# RockChip_RK3588 register map
Vendor: RockChip Electronics Co., Ltd.; Series: RK3588; File version: 0.1
Registers are 32-bit, read-write, no defined reset value unless marked. A register's access mark holds for its fields unless they carry their own. Offsets are from the block's base; [hi:lo] are bit positions; {n}, {i} and the like mark numbered series.

## PMU (part 2 of 3)
Base 0xFD8D0000
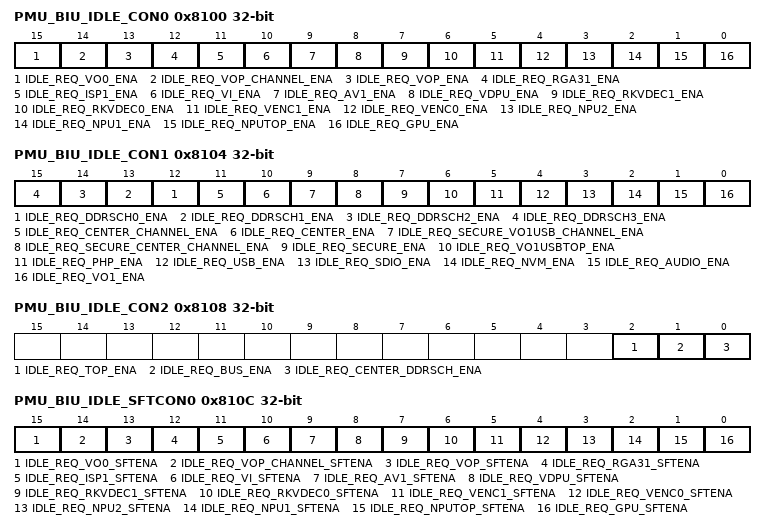
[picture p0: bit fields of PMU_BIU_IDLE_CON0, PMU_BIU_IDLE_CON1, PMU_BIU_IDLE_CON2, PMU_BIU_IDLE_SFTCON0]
0x8100 PMU_BIU_IDLE_CON0 — BIU idle request hardware control register 0
  [all] fields
    0=DISABLE; 1=ENABLE
  [15] IDLE_REQ_VO0_ENA — Enable sending idle request to BIU_VO0 by hardware.
  [14] IDLE_REQ_VOP_CHANNEL_ENA — Enable sending idle request to BIU_VOP_CHANNEL by hardware.
  [13] IDLE_REQ_VOP_ENA — Enable sending idle request to BIU_VOP by hardware.
  [12] IDLE_REQ_RGA31_ENA — Enable sending idle request to BIU_RGA31 by hardware.
  [11] IDLE_REQ_ISP1_ENA — Enable sending idle request to BIU_ISP1 by hardware.
  [10] IDLE_REQ_VI_ENA — Enable sending idle request to BIU_VI by hardware.
  [9] IDLE_REQ_AV1_ENA — Enable sending idle request to BIU_AV1 by hardware.
  [8] IDLE_REQ_VDPU_ENA — Enable sending idle request to BIU_VDPU by hardware.
  [7] IDLE_REQ_RKVDEC1_ENA — Enable sending idle request to BIU_RKVDEC1 by hardware.
  [6] IDLE_REQ_RKVDEC0_ENA — Enable sending idle request to BIU_RKVDEC0 by hardware.
  [5] IDLE_REQ_VENC1_ENA — Enable sending idle request to BIU_VENC1 by hardware.
  [4] IDLE_REQ_VENC0_ENA — Enable sending idle request to BIU_VENC0 by hardware.
  [3] IDLE_REQ_NPU2_ENA — Enable sending idle request to BIU_NPU2 by hardware.
  [2] IDLE_REQ_NPU1_ENA — Enable sending idle request to BIU_NPU1 by hardware.
  [1] IDLE_REQ_NPUTOP_ENA — Enable sending idle request to BIU_NPUTOP by hardware.
  [0] IDLE_REQ_GPU_ENA — Enable sending idle request to BIU_GPU by hardware.
0x8104 PMU_BIU_IDLE_CON1 — BIU idle request hardware control register 1
  [all] fields
    0=DISABLE; 1=ENABLE
  [n+12] IDLE_REQ_DDRSCH{n}_ENA (n=0..3) — Enable sending idle request to BIU_DDRSCH{n} by hardware.
  [11] IDLE_REQ_CENTER_CHANNEL_ENA — Enable sending idle request to BIU_CENTER_CHANNEL by hardware.
  [10] IDLE_REQ_CENTER_ENA — Enable sending idle request to BIU_CENTER by hardware.
  [9] IDLE_REQ_SECURE_VO1USB_CHANNEL_ENA — Enable sending idle request to BIU_SECURE_VO1USB_CHANNEL by hardware.
  [8] IDLE_REQ_SECURE_CENTER_CHANNEL_ENA — Enable sending idle request to BIU_SECURE_CENTER_CHANNEL by hardware.
  [7] IDLE_REQ_SECURE_ENA — Enable sending idle request to BIU_SECURE by hardware.
  [6] IDLE_REQ_VO1USBTOP_ENA — Enable sending idle request to BIU_VO1USBTOP by hardware.
  [5] IDLE_REQ_PHP_ENA — Enable sending idle request to BIU_PHP by hardware.
  [4] IDLE_REQ_USB_ENA — Enable sending idle request to BIU_USB by hardware.
  [3] IDLE_REQ_SDIO_ENA — Enable sending idle request to BIU_SDIO by hardware.
  [2] IDLE_REQ_NVM_ENA — Enable sending idle request to BIU_NVM by hardware.
  [1] IDLE_REQ_AUDIO_ENA — Enable sending idle request to BIU_AUDIO by hardware.
  [0] IDLE_REQ_VO1_ENA — Enable sending idle request to BIU_VO1 by hardware.
0x8108 PMU_BIU_IDLE_CON2 — BIU idle request hardware control register 2
  [all] fields
    0=DISABLE; 1=ENABLE
  [2] IDLE_REQ_TOP_ENA — Enable sending idle request to BIU_TOP by hardware.
  [1] IDLE_REQ_BUS_ENA — Enable sending idle request to BIU_BUS by hardware.
  [0] IDLE_REQ_CENTER_DDRSCH_ENA — Enable sending idle request to BIU_CENTER_DDRSCH by hardware.
0x810C PMU_BIU_IDLE_SFTCON0 — BIU idle request software control register 0
  [all] fields
    0=DISABLE; 1=ENABLE
  [15] IDLE_REQ_VO0_SFTENA — Enable sending idle request to BIU_VO0 by software.
  [14] IDLE_REQ_VOP_CHANNEL_SFTENA — Enable sending idle request to BIU_VOP_CHANNEL by software.
  [13] IDLE_REQ_VOP_SFTENA — Enable sending idle request to BIU_VOP by software.
  [12] IDLE_REQ_RGA31_SFTENA — Enable sending idle request to BIU_RGA31 by software.
  [11] IDLE_REQ_ISP1_SFTENA — Enable sending idle request to BIU_ISP1 by software.
  [10] IDLE_REQ_VI_SFTENA — Enable sending idle request to BIU_VI by software.
  [9] IDLE_REQ_AV1_SFTENA — Enable sending idle request to BIU_AV1 by software.
  [8] IDLE_REQ_VDPU_SFTENA — Enable sending idle request to BIU_VDPU by software.
  [7] IDLE_REQ_RKVDEC1_SFTENA — Enable sending idle request to BIU_RKVDEC1 by software.
  [6] IDLE_REQ_RKVDEC0_SFTENA — Enable sending idle request to BIU_RKVDEC0 by software.
  [5] IDLE_REQ_VENC1_SFTENA — Enable sending idle request to BIU_VENC1 by software.
  [4] IDLE_REQ_VENC0_SFTENA — Enable sending idle request to BIU_VENC0 by software.
  [3] IDLE_REQ_NPU2_SFTENA — Enable sending idle request to BIU_NPU2 by software.
  [2] IDLE_REQ_NPU1_SFTENA — Enable sending idle request to BIU_NPU1 by software.
  [1] IDLE_REQ_NPUTOP_SFTENA — Enable sending idle request to BIU_NPUTOP by software.
  [0] IDLE_REQ_GPU_SFTENA — Enable sending idle request to BIU_GPU by software.
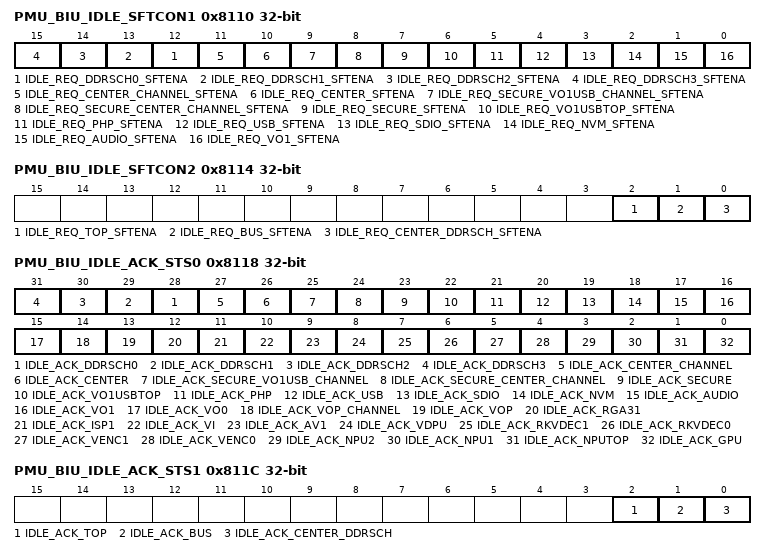
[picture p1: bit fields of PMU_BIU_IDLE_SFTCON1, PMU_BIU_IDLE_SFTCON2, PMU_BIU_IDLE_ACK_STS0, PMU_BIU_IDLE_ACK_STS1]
0x8110 PMU_BIU_IDLE_SFTCON1 — BIU idle request software control register 1
  [all] fields
    0=DISABLE; 1=ENABLE
  [n+12] IDLE_REQ_DDRSCH{n}_SFTENA (n=0..3) — Enable sending idle request to BIU_DDRSCH{n} by software.
  [11] IDLE_REQ_CENTER_CHANNEL_SFTENA — Enable sending idle request to BIU_CENTER_CHANNEL by software.
  [10] IDLE_REQ_CENTER_SFTENA — Enable sending idle request to BIU_CENTER by software.
  [9] IDLE_REQ_SECURE_VO1USB_CHANNEL_SFTENA — Enable sending idle request to BIU_SECURE_VO1USB_CHANNEL by software.
  [8] IDLE_REQ_SECURE_CENTER_CHANNEL_SFTENA — Enable sending idle request to BIU_SECURE_CENTER_CHANNEL by software.
  [7] IDLE_REQ_SECURE_SFTENA — Enable sending idle request to BIU_SECURE by software.
  [6] IDLE_REQ_VO1USBTOP_SFTENA — Enable sending idle request to BIU_VO1USBTOP by software.
  [5] IDLE_REQ_PHP_SFTENA — Enable sending idle request to BIU_PHP by software.
  [4] IDLE_REQ_USB_SFTENA — Enable sending idle request to BIU_USB by software.
  [3] IDLE_REQ_SDIO_SFTENA — Enable sending idle request to BIU_SDIO by software.
  [2] IDLE_REQ_NVM_SFTENA — Enable sending idle request to BIU_NVM by software.
  [1] IDLE_REQ_AUDIO_SFTENA — Enable sending idle request to BIU_AUDIO by software.
  [0] IDLE_REQ_VO1_SFTENA — Enable sending idle request to BIU_VO1 by software.
0x8114 PMU_BIU_IDLE_SFTCON2 — BIU idle request software control register 2
  [all] fields
    0=DISABLE; 1=ENABLE
  [2] IDLE_REQ_TOP_SFTENA — Enable sending idle request to BIU_TOP by software.
  [1] IDLE_REQ_BUS_SFTENA — Enable sending idle request to BIU_BUS by software.
  [0] IDLE_REQ_CENTER_DDRSCH_SFTENA — Enable sending idle request to BIU_CENTER_DDRSCH by software.
0x8118 PMU_BIU_IDLE_ACK_STS0 — BIU idle acknowledge status register 0
  [all] fields
    0=NAK; 1=ACK
  [n+28] IDLE_ACK_DDRSCH{n} ro (n=0..3) — BIU_DDRSCH{n} idle acknowledge state.
  [27] IDLE_ACK_CENTER_CHANNEL ro — BIU_CENTER_CHANNEL idle acknowledge state.
  [26] IDLE_ACK_CENTER ro — BIU_CENTER idle acknowledge state.
  [25] IDLE_ACK_SECURE_VO1USB_CHANNEL ro — BIU_SECURE_VO1USB_CHANNEL idle acknowledge state.
  [24] IDLE_ACK_SECURE_CENTER_CHANNEL ro — BIU_SECURE_CENTER_CHANNEL idle acknowledge state.
  [23] IDLE_ACK_SECURE ro — BIU_SECURE idle acknowledge state.
  [22] IDLE_ACK_VO1USBTOP ro — BIU_VO1USBTOP idle acknowledge state.
  [21] IDLE_ACK_PHP ro — BIU_PHP idle acknowledge state.
  [20] IDLE_ACK_USB ro — BIU_USB idle acknowledge state.
  [19] IDLE_ACK_SDIO ro — BIU_SDIO idle acknowledge state.
  [18] IDLE_ACK_NVM ro — BIU_NVM idle acknowledge state.
  [17] IDLE_ACK_AUDIO ro — BIU_AUDIO idle acknowledge state.
  [16] IDLE_ACK_VO1 ro — BIU_VO1 idle acknowledge state.
  [15] IDLE_ACK_VO0 ro — BIU_VO0 idle acknowledge state.
  [14] IDLE_ACK_VOP_CHANNEL ro — BIU_VOP_CHANNEL idle acknowledge state.
  [13] IDLE_ACK_VOP ro — BIU_VOP idle acknowledge state.
  [12] IDLE_ACK_RGA31 ro — BIU_RGA31 idle acknowledge state.
  [11] IDLE_ACK_ISP1 ro — BIU_ISP1 idle acknowledge state.
  [10] IDLE_ACK_VI ro — BIU_VI idle acknowledge state.
  [9] IDLE_ACK_AV1 ro — BIU_AV1 idle acknowledge state.
  [8] IDLE_ACK_VDPU ro — BIU_VDPU idle acknowledge state.
  [7] IDLE_ACK_RKVDEC1 ro — BIU_RKVDEC1 idle acknowledge state.
  [6] IDLE_ACK_RKVDEC0 ro — BIU_RKVDEC0 idle acknowledge state.
  [5] IDLE_ACK_VENC1 ro — BIU_VENC1 idle acknowledge state.
  [4] IDLE_ACK_VENC0 ro — BIU_VENC0 idle acknowledge state.
  [3] IDLE_ACK_NPU2 ro — BIU_NPU2 idle acknowledge state.
  [2] IDLE_ACK_NPU1 ro — BIU_NPU1 idle acknowledge state.
  [1] IDLE_ACK_NPUTOP ro — BIU_NPUTOP idle acknowledge state.
  [0] IDLE_ACK_GPU ro — BIU_GPU idle acknowledge state.
0x811C PMU_BIU_IDLE_ACK_STS1 — BIU idle acknowledge status register 1
  [all] fields
    0=NAK; 1=ACK
  [2] IDLE_ACK_TOP ro — BIU_TOP idle acknowledge state.
  [1] IDLE_ACK_BUS ro — BIU_BUS idle acknowledge state.
  [0] IDLE_ACK_CENTER_DDRSCH ro — BIU_CENTER_DDRSCH idle acknowledge state.
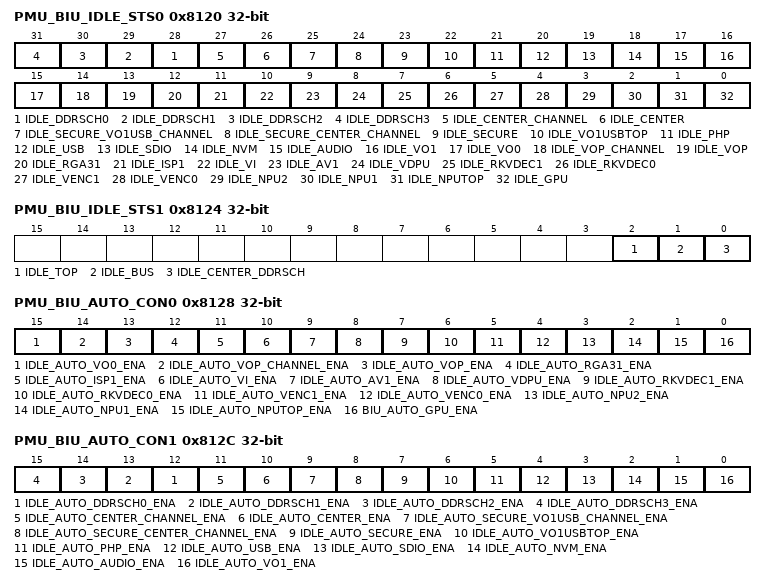
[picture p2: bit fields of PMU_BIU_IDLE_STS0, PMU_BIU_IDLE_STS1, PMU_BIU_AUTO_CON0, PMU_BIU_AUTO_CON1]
0x8120 PMU_BIU_IDLE_STS0 — BIU idle status register 0
  [all] fields
    0=NOT_IDLE; 1=IDLE
  [n+28] IDLE_DDRSCH{n} ro (n=0..3) — BIU_DDRSCH{n} idle state.
  [27] IDLE_CENTER_CHANNEL ro — BIU_CENTER_CHANNEL idle state.
  [26] IDLE_CENTER ro — BIU_CENTER idle state.
  [25] IDLE_SECURE_VO1USB_CHANNEL ro — BIU_SECURE_VO1USB_CHANNEL idle state.
  [24] IDLE_SECURE_CENTER_CHANNEL ro — BIU_SECURE_CENTER_CHANNEL idle state.
  [23] IDLE_SECURE ro — BIU_SECURE idle state.
  [22] IDLE_VO1USBTOP ro — BIU_VO1USBTOP idle state.
  [21] IDLE_PHP ro — BIU_PHP idle state.
  [20] IDLE_USB ro — BIU_USB idle state.
  [19] IDLE_SDIO ro — BIU_SDIO idle state.
  [18] IDLE_NVM ro — BIU_NVM idle state.
  [17] IDLE_AUDIO ro — BIU_AUDIO idle state.
  [16] IDLE_VO1 ro — BIU_VO1 idle state.
  [15] IDLE_VO0 ro — BIU_VO0 idle state.
  [14] IDLE_VOP_CHANNEL ro — BIU_VOP_CHANNEL idle state.
  [13] IDLE_VOP ro — BIU_VOP idle state.
  [12] IDLE_RGA31 ro — BIU_RGA31 idle state.
  [11] IDLE_ISP1 ro — BIU_ISP1 idle state.
  [10] IDLE_VI ro — BIU_VI idle state.
  [9] IDLE_AV1 ro — BIU_AV1 idle state.
  [8] IDLE_VDPU ro — BIU_VDPU idle state.
  [7] IDLE_RKVDEC1 ro — BIU_RKVDEC1 idle state.
  [6] IDLE_RKVDEC0 ro — BIU_RKVDEC0 idle state.
  [5] IDLE_VENC1 ro — BIU_VENC1 idle state.
  [4] IDLE_VENC0 ro — BIU_VENC0 idle state.
  [3] IDLE_NPU2 ro — BIU_NPU2 idle state.
  [2] IDLE_NPU1 ro — BIU_NPU1 idle state.
  [1] IDLE_NPUTOP ro — BIU_NPUTOP idle state.
  [0] IDLE_GPU ro — BIU_GPU idle state.
0x8124 PMU_BIU_IDLE_STS1 — BIU idle status register 1
  [all] fields
    0=NOT_IDLE; 1=IDLE
  [2] IDLE_TOP ro — BIU_TOP idle state.
  [1] IDLE_BUS ro — BIU_BUS idle state.
  [0] IDLE_CENTER_DDRSCH ro — BIU_CENTER_DDRSCH idle state.
0x8128 PMU_BIU_AUTO_CON0 — BIU automatic power control register 0
  [all] fields
    0=DISABLE; 1=ENABLE
  [15] IDLE_AUTO_VO0_ENA — If enable, BIU_VO0 corresponding clock can be opened or gated automatically when idle operation.
  [14] IDLE_AUTO_VOP_CHANNEL_ENA — If enable, BIU_VOP_CHANNEL corresponding clock can be opened or gated automatically when idle operation.
  [13] IDLE_AUTO_VOP_ENA — If enable, BIU_VOP corresponding clock can be opened or gated automatically when idle operation.
  [12] IDLE_AUTO_RGA31_ENA — If enable, BIU_RGA31 corresponding clock can be opened or gated automatically when idle operation.
  [11] IDLE_AUTO_ISP1_ENA — If enable, BIU_ISP1 corresponding clock can be opened or gated automatically when idle operation.
  [10] IDLE_AUTO_VI_ENA — If enable, BIU_VI corresponding clock can be opened or gated automatically when idle operation.
  [9] IDLE_AUTO_AV1_ENA — If enable, BIU_AV1 corresponding clock can be opened or gated automatically when idle operation.
  [8] IDLE_AUTO_VDPU_ENA — If enable, BIU_VDPU corresponding clock can be opened or gated automatically when idle operation.
  [7] IDLE_AUTO_RKVDEC1_ENA — If enable, BIU_RKVDEC1 corresponding clock can be opened or gated automatically when idle operation.
  [6] IDLE_AUTO_RKVDEC0_ENA — If enable, BIU_RKVDEC0 corresponding clock can be opened or gated automatically when idle operation.
  [5] IDLE_AUTO_VENC1_ENA — If enable, BIU_VENC1 corresponding clock can be opened or gated automatically when idle operation.
  [4] IDLE_AUTO_VENC0_ENA — If enable, BIU_VENC0 corresponding clock can be opened or gated automatically when idle operation.
  [3] IDLE_AUTO_NPU2_ENA — If enable, BIU_NPU2 corresponding clock can be opened or gated automatically when idle operation.
  [2] IDLE_AUTO_NPU1_ENA — If enable, BIU_NPU1 corresponding clock can be opened or gated automatically when idle operation.
  [1] IDLE_AUTO_NPUTOP_ENA — If enable, BIU_NPUTOP corresponding clock can be opened or gated automatically when idle operation.
  [0] BIU_AUTO_GPU_ENA — If enable, BIU_GPU corresponding clock can be opened or gated automatically when idle operation.
0x812C PMU_BIU_AUTO_CON1 — BIU automatic power control register 1
  [all] fields
    0=DISABLE; 1=ENABLE
  [n+12] IDLE_AUTO_DDRSCH{n}_ENA (n=0..3) — If enable, BIU_DDRSCH{n} corresponding clock can be opened or gated automatically when idle operation.
  [11] IDLE_AUTO_CENTER_CHANNEL_ENA — If enable, BIU_CENTER_CHANNEL corresponding clock can be opened or gated automatically when idle operation.
  [10] IDLE_AUTO_CENTER_ENA — If enable, BIU_CENTER corresponding clock can be opened or gated automatically when idle operation.
  [9] IDLE_AUTO_SECURE_VO1USB_CHANNEL_ENA — If enable, BIU_SECURE_VO1USB_CHANNEL corresponding clock can be opened or gated automatically when idle operation.
  [8] IDLE_AUTO_SECURE_CENTER_CHANNEL_ENA — If enable, BIU_SECURE_CENTER_CHANNEL corresponding clock can be opened or gated automatically when idle operation.
  [7] IDLE_AUTO_SECURE_ENA — If enable, BIU_SECURE corresponding clock can be opened or gated automatically when idle operation.
  [6] IDLE_AUTO_VO1USBTOP_ENA — If enable, BIU_VO1USBTOP corresponding clock can be opened or gated automatically when idle operation.
  [5] IDLE_AUTO_PHP_ENA — If enable, BIU_PHP corresponding clock can be opened or gated automatically when idle operation.
  [4] IDLE_AUTO_USB_ENA — If enable, BIU_USB corresponding clock can be opened or gated automatically when idle operation.
  [3] IDLE_AUTO_SDIO_ENA — If enable, BIU_SDIO corresponding clock can be opened or gated automatically when idle operation.
  [2] IDLE_AUTO_NVM_ENA — If enable, BIU_NVM corresponding clock can be opened or gated automatically when idle operation.
  [1] IDLE_AUTO_AUDIO_ENA — If enable, BIU_AUDIO corresponding clock can be opened or gated automatically when idle operation.
  [0] IDLE_AUTO_VO1_ENA — If enable, BIU_VO1 corresponding clock can be opened or gated automatically when idle operation.
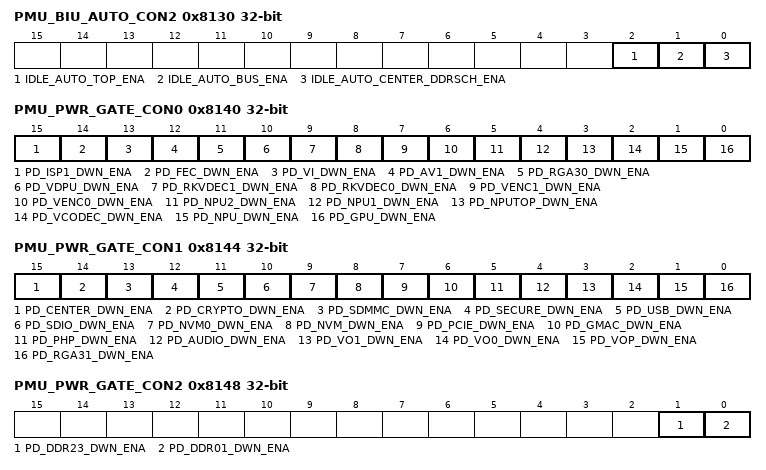
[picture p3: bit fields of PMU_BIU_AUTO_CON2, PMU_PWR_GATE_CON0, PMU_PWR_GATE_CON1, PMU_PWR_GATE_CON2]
0x8130 PMU_BIU_AUTO_CON2 — BIU automatic power control register 2
  [all] fields
    0=DISABLE; 1=ENABLE
  [2] IDLE_AUTO_TOP_ENA — If enable, BIU_TOP corresponding clock can be opened or gated automatically when idle operation.
  [1] IDLE_AUTO_BUS_ENA — If enable, BIU_BUS corresponding clock can be opened or gated automatically when idle operation.
  [0] IDLE_AUTO_CENTER_DDRSCH_ENA — If enable, BIU_CENTER_DDRSCH corresponding clock can be opened or gated automatically when idle operation.
0x8140 PMU_PWR_GATE_CON0 — Power domain hardware power control register 0
  [all] fields
    0=DISABLE; 1=ENABLE
  [15] PD_ISP1_DWN_ENA — Enable power down PD_ISP1 by hardware.
  [14] PD_FEC_DWN_ENA — Enable power down PD_FEC by hardware.
  [13] PD_VI_DWN_ENA — Enable power down PD_VI by hardware.
  [12] PD_AV1_DWN_ENA — Enable power down PD_AV1 by hardware.
  [11] PD_RGA30_DWN_ENA — Enable power down PD_RGA30 by hardware.
  [10] PD_VDPU_DWN_ENA — Enable power down PD_VDPU by hardware.
  [9] PD_RKVDEC1_DWN_ENA — Enable power down PD_RKVDEC1 by hardware.
  [8] PD_RKVDEC0_DWN_ENA — Enable power down PD_RKVDEC0 by hardware.
  [7] PD_VENC1_DWN_ENA — Enable power down PD_VENC1 by hardware.
  [6] PD_VENC0_DWN_ENA — Enable power down PD_VENC0 by hardware.
  [5] PD_NPU2_DWN_ENA — Enable power down PD_NPU2 by hardware.
  [4] PD_NPU1_DWN_ENA — Enable power down PD_NPU1 by hardware.
  [3] PD_NPUTOP_DWN_ENA — Enable power down PD_NPUTOP by hardware.
  [2] PD_VCODEC_DWN_ENA — Enable power down VD_VCODEC by hardware.
  [1] PD_NPU_DWN_ENA — Enable power down VD_NPU by hardware.
  [0] PD_GPU_DWN_ENA — Enable power down VD_GPU by hardware.
0x8144 PMU_PWR_GATE_CON1 — Power domain hardware power control register 1
  [all] fields
    0=DISABLE; 1=ENABLE
  [15] PD_CENTER_DWN_ENA — Enable power down PD_CENTER by hardware.
  [14] PD_CRYPTO_DWN_ENA — Enable power down PD_CRYPTO by hardware.
  [13] PD_SDMMC_DWN_ENA — Enable power down PD_SDMMC by hardware.
  [12] PD_SECURE_DWN_ENA — Enable power down PD_SECURE by hardware.
  [11] PD_USB_DWN_ENA — Enable power down PD_USB by hardware.
  [10] PD_SDIO_DWN_ENA — Enable power down PD_SDIO by hardware.
  [9] PD_NVM0_DWN_ENA — Enable power down PD_NVM0 by hardware.
  [8] PD_NVM_DWN_ENA — Enable power down PD_NVM by hardware.
  [7] PD_PCIE_DWN_ENA — Enable power down PD_PCIE by hardware.
  [6] PD_GMAC_DWN_ENA — Enable power down PD_GMAC by hardware.
  [5] PD_PHP_DWN_ENA — Enable power down PD_PHP by hardware.
  [4] PD_AUDIO_DWN_ENA — Enable power down PD_AUDIO by hardware.
  [3] PD_VO1_DWN_ENA — Enable power down PD_VO1 by hardware.
  [2] PD_VO0_DWN_ENA — Enable power down PD_VO0 by hardware.
  [1] PD_VOP_DWN_ENA — Enable power down PD_VOP by hardware.
  [0] PD_RGA31_DWN_ENA — Enable power down PD_RGA31 by hardware.
0x8148 PMU_PWR_GATE_CON2 — Power domain hardware power control register 2
  [1] PD_DDR23_DWN_ENA — Enable power down VD_DDR23 by hardware.
    0=DISABLE; 1=ENABLE
  [0] PD_DDR01_DWN_ENA — Enable power down VD_DDR01 by hardware.
    0=DISABLE; 1=ENABLE
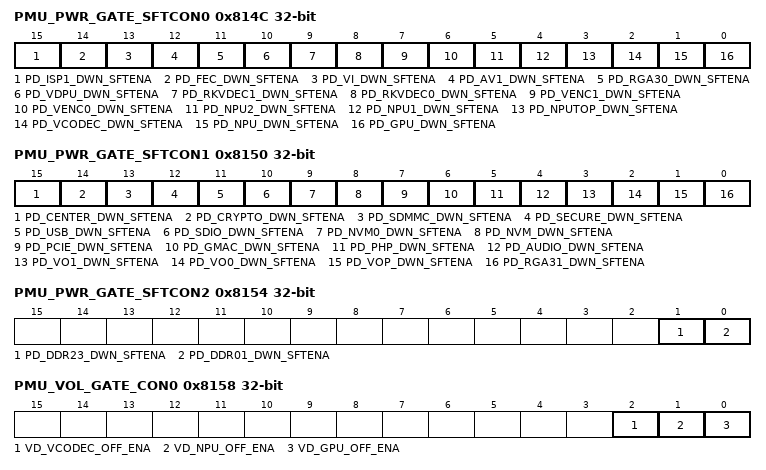
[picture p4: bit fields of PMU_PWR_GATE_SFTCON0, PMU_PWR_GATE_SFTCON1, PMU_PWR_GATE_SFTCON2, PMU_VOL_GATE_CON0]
0x814C PMU_PWR_GATE_SFTCON0 — Power domain software power control register 0
  [all] fields
    0=DISABLE; 1=ENABLE
  [15] PD_ISP1_DWN_SFTENA — Enable power down PD_ISP1 by software.
  [14] PD_FEC_DWN_SFTENA — Enable power down PD_FEC by software.
  [13] PD_VI_DWN_SFTENA — Enable power down PD_VI by software.
  [12] PD_AV1_DWN_SFTENA — Enable power down PD_AV1 by software.
  [11] PD_RGA30_DWN_SFTENA — Enable power down PD_RGA30 by software.
  [10] PD_VDPU_DWN_SFTENA — Enable power down PD_VDPU by software.
  [9] PD_RKVDEC1_DWN_SFTENA — Enable power down PD_RKVDEC1 by software.
  [8] PD_RKVDEC0_DWN_SFTENA — Enable power down PD_RKVDEC0 by software.
  [7] PD_VENC1_DWN_SFTENA — Enable power down PD_VENC1 by software.
  [6] PD_VENC0_DWN_SFTENA — Enable power down PD_VENC0 by software.
  [5] PD_NPU2_DWN_SFTENA — Enable power down PD_NPU2 by software.
  [4] PD_NPU1_DWN_SFTENA — Enable power down PD_NPU1 by software.
  [3] PD_NPUTOP_DWN_SFTENA — Enable power down PD_NPUTOP by software.
  [2] PD_VCODEC_DWN_SFTENA — Enable power down VD_VCODEC by software.
  [1] PD_NPU_DWN_SFTENA — Enable power down VD_NPU by software.
  [0] PD_GPU_DWN_SFTENA — Enable power down VD_GPU by software.
0x8150 PMU_PWR_GATE_SFTCON1 — Power domain software power control register 1
  [all] fields
    0=DISABLE; 1=ENABLE
  [15] PD_CENTER_DWN_SFTENA — Enable power down PD_CENTER by software.
  [14] PD_CRYPTO_DWN_SFTENA — Enable power down PD_CRYPTO by software.
  [13] PD_SDMMC_DWN_SFTENA — Enable power down PD_SDMMC by software.
  [12] PD_SECURE_DWN_SFTENA — Enable power down PD_SECURE by software.
  [11] PD_USB_DWN_SFTENA — Enable power down PD_USB by software.
  [10] PD_SDIO_DWN_SFTENA — Enable power down PD_SDIO by software.
  [9] PD_NVM0_DWN_SFTENA — Enable power down PD_NVM0 by software.
  [8] PD_NVM_DWN_SFTENA — Enable power down PD_NVM by software.
  [7] PD_PCIE_DWN_SFTENA — Enable power down PD_PCIE by software.
  [6] PD_GMAC_DWN_SFTENA — Enable power down PD_GMAC by software.
  [5] PD_PHP_DWN_SFTENA — Enable power down PD_PHP by software.
  [4] PD_AUDIO_DWN_SFTENA — Enable power down PD_AUDIO by software.
  [3] PD_VO1_DWN_SFTENA — Enable power down PD_VO1 by software.
  [2] PD_VO0_DWN_SFTENA — Enable power down PD_VO0 by software.
  [1] PD_VOP_DWN_SFTENA — Enable power down PD_VOP by software.
  [0] PD_RGA31_DWN_SFTENA — Enable power down PD_RGA31 by software.
0x8154 PMU_PWR_GATE_SFTCON2 — Power domain software power control register 2
  [1] PD_DDR23_DWN_SFTENA — Enable power down VD_DDR23 by software.
    0=DISABLE; 1=ENABLE
  [0] PD_DDR01_DWN_SFTENA — Enable power down VD_DDR01 by software.
    0=DISABLE; 1=ENABLE
0x8158 PMU_VOL_GATE_CON0 — Voltage domain power control register 0
  [all] fields
    0=DISABLE; 1=ENABLE
  [2] VD_VCODEC_OFF_ENA — Enable power off VD_VCODEC.
  [1] VD_NPU_OFF_ENA — Enable power off VD_NPU.
  [0] VD_GPU_OFF_ENA — Enable power off VD_GPU.
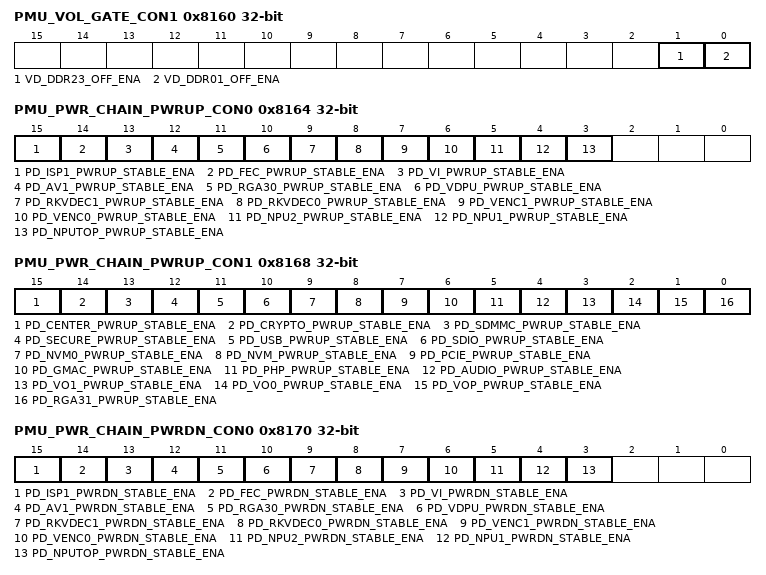
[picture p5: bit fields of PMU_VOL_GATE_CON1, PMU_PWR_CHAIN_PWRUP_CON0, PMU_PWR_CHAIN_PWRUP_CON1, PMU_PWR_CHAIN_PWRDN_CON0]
0x8160 PMU_VOL_GATE_CON1 — Voltage domain power control register 1
  [1] VD_DDR23_OFF_ENA — Enable power off VD_DDR23.
    0=DISABLE; 1=ENABLE
  [0] VD_DDR01_OFF_ENA — Enable power off VD_DDR01.
    0=DISABLE; 1=ENABLE
0x8164 PMU_PWR_CHAIN_PWRUP_CON0 — Power chain stable control register 0 for power up
  [all] fields
    0=DISABLE; 1=ENABLE
  [15] PD_ISP1_PWRUP_STABLE_ENA — Enable stable counter between power chains for PD_ISP1 power up flow.
  [14] PD_FEC_PWRUP_STABLE_ENA — Enable stable counter between power chains for PD_FEC power up flow.
  [13] PD_VI_PWRUP_STABLE_ENA — Enable stable counter between power chains for PD_VI power up flow.
  [12] PD_AV1_PWRUP_STABLE_ENA — Enable stable counter between power chains for PD_AV1 power up flow.
  [11] PD_RGA30_PWRUP_STABLE_ENA — Enable stable counter between power chains for PD_RGA30 power up flow.
  [10] PD_VDPU_PWRUP_STABLE_ENA — Enable stable counter between power chains for PD_VDPU power up flow.
  [9] PD_RKVDEC1_PWRUP_STABLE_ENA — Enable stable counter between power chains for PD_RKVDEC1 power up flow.
  [8] PD_RKVDEC0_PWRUP_STABLE_ENA — Enable stable counter between power chains for PD_RKVDEC0 power up flow.
  [7] PD_VENC1_PWRUP_STABLE_ENA — Enable stable counter between power chains for PD_VENC1 power up flow.
  [6] PD_VENC0_PWRUP_STABLE_ENA — Enable stable counter between power chains for PD_VENC0 power up flow.
  [5] PD_NPU2_PWRUP_STABLE_ENA — Enable stable counter between power chains for PD_NPU2 power up flow.
  [4] PD_NPU1_PWRUP_STABLE_ENA — Enable stable counter between power chains for PD_NPU1 power up flow.
  [3] PD_NPUTOP_PWRUP_STABLE_ENA — Enable stable counter between power chains for PD_NPUTOP power up flow.
0x8168 PMU_PWR_CHAIN_PWRUP_CON1 — Power chain stable control register 1 for power up
  [all] fields
    0=DISABLE; 1=ENABLE
  [15] PD_CENTER_PWRUP_STABLE_ENA — Enable stable counter between power chains for PD_CENTER power up flow.
  [14] PD_CRYPTO_PWRUP_STABLE_ENA — Enable stable counter between power chains for PD_CRYPTO power up flow.
  [13] PD_SDMMC_PWRUP_STABLE_ENA — Enable stable counter between power chains for PD_SDMMC power up flow.
  [12] PD_SECURE_PWRUP_STABLE_ENA — Enable stable counter between power chains for PD_SECURE power up flow.
  [11] PD_USB_PWRUP_STABLE_ENA — Enable stable counter between power chains for PD_USB power up flow.
  [10] PD_SDIO_PWRUP_STABLE_ENA — Enable stable counter between power chains for PD_SDIO power up flow.
  [9] PD_NVM0_PWRUP_STABLE_ENA — Enable stable counter between power chains for PD_NVM0 power up flow.
  [8] PD_NVM_PWRUP_STABLE_ENA — Enable stable counter between power chains for PD_NVM power up flow.
  [7] PD_PCIE_PWRUP_STABLE_ENA — Enable stable counter between power chains for PD_PCIE power up flow.
  [6] PD_GMAC_PWRUP_STABLE_ENA — Enable stable counter between power chains for PD_GMAC power up flow.
  [5] PD_PHP_PWRUP_STABLE_ENA — Enable stable counter between power chains for PD_PHP power up flow.
  [4] PD_AUDIO_PWRUP_STABLE_ENA — Enable stable counter between power chains for PD_AUDIO power up flow.
  [3] PD_VO1_PWRUP_STABLE_ENA — Enable stable counter between power chains for PD_VO1 power up flow.
  [2] PD_VO0_PWRUP_STABLE_ENA — Enable stable counter between power chains for PD_VO0 power up flow.
  [1] PD_VOP_PWRUP_STABLE_ENA — Enable stable counter between power chains for PD_VOP power up flow.
  [0] PD_RGA31_PWRUP_STABLE_ENA — Enable stable counter between power chains for PD_RGA31 power up flow.
0x8170 PMU_PWR_CHAIN_PWRDN_CON0 — Power chain stable control register 0 for power down
  [all] fields
    0=DISABLE; 1=ENABLE
  [15] PD_ISP1_PWRDN_STABLE_ENA — Enable stable counter between power chains for PD_ISP1 power down flow.
  [14] PD_FEC_PWRDN_STABLE_ENA — Enable stable counter between power chains for PD_FEC power down flow.
  [13] PD_VI_PWRDN_STABLE_ENA — Enable stable counter between power chains for PD_VI power down flow.
  [12] PD_AV1_PWRDN_STABLE_ENA — Enable stable counter between power chains for PD_AV1 power down flow.
  [11] PD_RGA30_PWRDN_STABLE_ENA — Enable stable counter between power chains for PD_RGA30 power down flow.
  [10] PD_VDPU_PWRDN_STABLE_ENA — Enable stable counter between power chains for PD_VDPU power down flow.
  [9] PD_RKVDEC1_PWRDN_STABLE_ENA — Enable stable counter between power chains for PD_RKVDEC1 power down flow.
  [8] PD_RKVDEC0_PWRDN_STABLE_ENA — Enable stable counter between power chains for PD_RKVDEC0 power down flow.
  [7] PD_VENC1_PWRDN_STABLE_ENA — Enable stable counter between power chains for PD_VENC1 power down flow.
  [6] PD_VENC0_PWRDN_STABLE_ENA — Enable stable counter between power chains for PD_VENC0 power down flow.
  [5] PD_NPU2_PWRDN_STABLE_ENA — Enable stable counter between power chains for PD_NPU2 power down flow.
  [4] PD_NPU1_PWRDN_STABLE_ENA — Enable stable counter between power chains for PD_NPU1 power down flow.
  [3] PD_NPUTOP_PWRDN_STABLE_ENA — Enable stable counter between power chains for PD_NPUTOP power down flow.
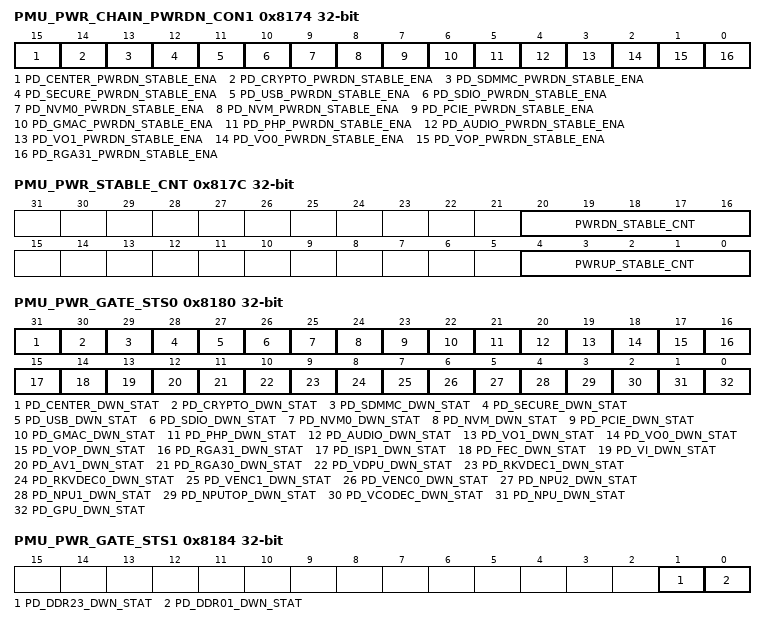
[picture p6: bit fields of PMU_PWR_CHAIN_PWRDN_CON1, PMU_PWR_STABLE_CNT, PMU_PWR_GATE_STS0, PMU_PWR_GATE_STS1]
0x8174 PMU_PWR_CHAIN_PWRDN_CON1 — Power chain stable control register 1 for power down
  [all] fields
    0=DISABLE; 1=ENABLE
  [15] PD_CENTER_PWRDN_STABLE_ENA — Enable stable counter between power chains for PD_CENTER power down flow.
  [14] PD_CRYPTO_PWRDN_STABLE_ENA — Enable stable counter between power chains for PD_CRYPTO power down flow.
  [13] PD_SDMMC_PWRDN_STABLE_ENA — Enable stable counter between power chains for PD_SDMMC power down flow.
  [12] PD_SECURE_PWRDN_STABLE_ENA — Enable stable counter between power chains for PD_SECURE power down flow.
  [11] PD_USB_PWRDN_STABLE_ENA — Enable stable counter between power chains for PD_USB power down flow.
  [10] PD_SDIO_PWRDN_STABLE_ENA — Enable stable counter between power chains for PD_SDIO power down flow.
  [9] PD_NVM0_PWRDN_STABLE_ENA — Enable stable counter between power chains for PD_NVM0 power down flow.
  [8] PD_NVM_PWRDN_STABLE_ENA — Enable stable counter between power chains for PD_NVM power down flow.
  [7] PD_PCIE_PWRDN_STABLE_ENA — Enable stable counter between power chains for PD_PCIE power down flow.
  [6] PD_GMAC_PWRDN_STABLE_ENA — Enable stable counter between power chains for PD_GMAC power down flow.
  [5] PD_PHP_PWRDN_STABLE_ENA — Enable stable counter between power chains for PD_PHP power down flow.
  [4] PD_AUDIO_PWRDN_STABLE_ENA — Enable stable counter between power chains for PD_AUDIO power down flow.
  [3] PD_VO1_PWRDN_STABLE_ENA — Enable stable counter between power chains for PD_VO1 power down flow.
  [2] PD_VO0_PWRDN_STABLE_ENA — Enable stable counter between power chains for PD_VO0 power down flow.
  [1] PD_VOP_PWRDN_STABLE_ENA — Enable stable counter between power chains for PD_VOP power down flow.
  [0] PD_RGA31_PWRDN_STABLE_ENA — Enable stable counter between power chains for PD_RGA31 power down flow.
0x817C PMU_PWR_STABLE_CNT — Power chain stable count register
  [20:16] PWRDN_STABLE_CNT — Count for power chain power down stability. Number of clk_pmu used by counter logic.
  [4:0] PWRUP_STABLE_CNT — Count for power chain power up stability. Number of clk_pmu used by counter logic.
0x8180 PMU_PWR_GATE_STS0 — Power domain power status register 0
  [all] fields
    0=POWER_UP; 1=POWER_DOWN
  [31] PD_CENTER_DWN_STAT ro — The power state of PD_CENTER.
  [30] PD_CRYPTO_DWN_STAT ro — The power state of PD_CRYPTO.
  [29] PD_SDMMC_DWN_STAT ro — The power state of PD_SDMMC.
  [28] PD_SECURE_DWN_STAT ro — The power state of PD_SECURE.
  [27] PD_USB_DWN_STAT ro — The power state of PD_USB.
  [26] PD_SDIO_DWN_STAT ro — The power state of PD_SDIO.
  [25] PD_NVM0_DWN_STAT ro — The power state of PD_NVM0.
  [24] PD_NVM_DWN_STAT ro — The power state of PD_NVM.
  [23] PD_PCIE_DWN_STAT ro — The power state of PD_PCIE.
  [22] PD_GMAC_DWN_STAT ro — The power state of PD_GMAC.
  [21] PD_PHP_DWN_STAT ro — The power state of PD_PHP.
  [20] PD_AUDIO_DWN_STAT ro — The power state of PD_AUDIO.
  [19] PD_VO1_DWN_STAT ro — The power state of PD_VO1.
  [18] PD_VO0_DWN_STAT ro — The power state of PD_VO0.
  [17] PD_VOP_DWN_STAT ro — The power state of PD_VOP.
  [16] PD_RGA31_DWN_STAT ro — The power state of PD_RGA31.
  [15] PD_ISP1_DWN_STAT ro — The power state of PD_ISP1.
  [14] PD_FEC_DWN_STAT ro — The power state of PD_FEC.
  [13] PD_VI_DWN_STAT ro — The power state of PD_VI.
  [12] PD_AV1_DWN_STAT ro — The power state of PD_AV1.
  [11] PD_RGA30_DWN_STAT ro — The power state of PD_RGA30.
  [10] PD_VDPU_DWN_STAT ro — The power state of PD_VDPU.
  [9] PD_RKVDEC1_DWN_STAT ro — The power state of PD_RKVDEC1.
  [8] PD_RKVDEC0_DWN_STAT ro — The power state of PD_RKVDEC0.
  [7] PD_VENC1_DWN_STAT ro — The power state of PD_VENC1.
  [6] PD_VENC0_DWN_STAT ro — The power state of PD_VENC0.
  [5] PD_NPU2_DWN_STAT ro — The power state of PD_NPU2.
  [4] PD_NPU1_DWN_STAT ro — The power state of PD_NPU1.
  [3] PD_NPUTOP_DWN_STAT ro — The power state of PD_NPUTOP.
  [2] PD_VCODEC_DWN_STAT ro — The power state of VD_VCODEC.
  [1] PD_NPU_DWN_STAT ro — The power state of VD_NPU.
  [0] PD_GPU_DWN_STAT ro — The power state of VD_GPU.
0x8184 PMU_PWR_GATE_STS1 — Power domain power status register 1
  [1] PD_DDR23_DWN_STAT ro — The power state of VD_DDR23.
    0=POWER_UP; 1=POWER_DOWN
  [0] PD_DDR01_DWN_STAT ro — The power state of VD_DDR01.
    0=POWER_UP; 1=POWER_DOWN
0x8188 PMU_PWR_GATE_POWER_STS — Power gating status register
  [2:0] POWER_GATE_STATE ro — Power gating state. Others: Reserved
    0=Normal state; 1=Power down start state; 2=Power down running state; 3=Wait for power up state; 4=Power up start state; 5=Power up running state
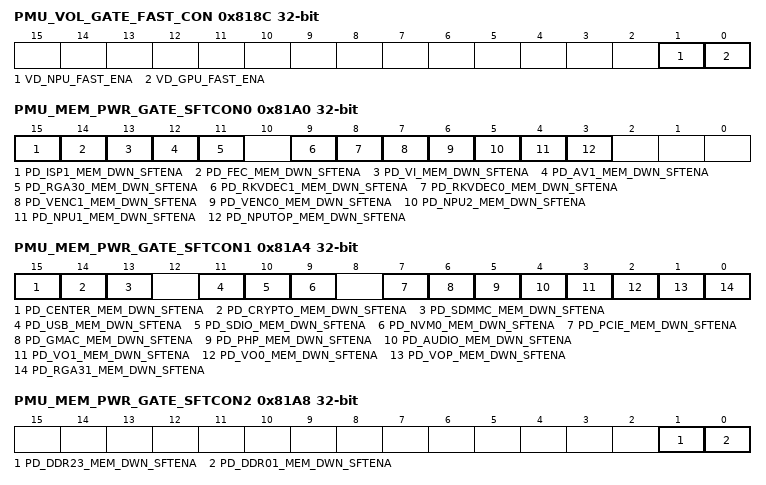
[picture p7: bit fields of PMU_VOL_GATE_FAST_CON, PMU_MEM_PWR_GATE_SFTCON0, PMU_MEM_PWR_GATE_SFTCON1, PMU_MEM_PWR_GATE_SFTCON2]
0x818C PMU_VOL_GATE_FAST_CON — Voltage domain fast power control register
  [1] VD_NPU_FAST_ENA — Enable VD_NPU fast power control. When asserted, it means that VD_NPU will power up completely if VD_NPU power up count from npu_pwrup_cnt (defined in PMU_NPU_PWRUP_CNT) to zero when VD_NPU power up request active, or VD_NPU will power down completely if VD_NPU power down count from npu_pwrdn_cnt (defined in PMU_NPU_PWRDN_CNT) to zero when VD_NPU power down request active. Otherwise, it means that VD_NPU will power up completely as soon as VD_NPU power up request active, or power down completely as soon as VD_NPU power down request active.
    0=DISABLE; 1=ENABLE
  [0] VD_GPU_FAST_ENA — Enable VD_GPU fast power control. When asserted, it means that VD_GPU will power up completely if VD_GPU power up count from gpu_pwrup_cnt (defined in PMU_GPU_PWRUP_CNT) to zero when VD_GPU power up request active, or VD_GPU will power down completely if VD_GPU power down count from gpu_pwrdn_cnt (defined in PMU_GPU_PWRDN_CNT) to zero when VD_GPU power down request active. Otherwise, it means that VD_GPU will power up completely as soon as VD_GPU power up request active, or power down completely as soon as VD_GPU power down request active.
    0=DISABLE; 1=ENABLE
0x8190 PMU_GPU_PWRUP_CNT — VD_GPU power up count register
  [19:0] GPU_PWRUP_CNT — VD_GPU power up count. Number of clk_pmu used by counter logic.
0x8194 PMU_GPU_PWRDN_CNT — VD_GPU power down count register
  [19:0] GPU_PWRDN_CNT — VD_GPU power down count. Number of clk_pmu used by counter logic.
0x8198 PMU_NPU_PWRUP_CNT — VD_NPU power up count register
  [19:0] NPU_PWRUP_CNT — VD_NPU power up count. Number of clk_pmu used by counter logic.
0x819C PMU_NPU_PWRDN_CNT — VD_NPU power down count register
  [19:0] NPU_PWRDN_CNT — VD_NPU power down count. Number of clk_pmu used by counter logic.
0x81A0 PMU_MEM_PWR_GATE_SFTCON0 — Memory software power control register 0
  [all] fields
    0=DISABLE; 1=ENABLE
  [15] PD_ISP1_MEM_DWN_SFTENA — Enable power down PD_ISP1's memory by software.
  [14] PD_FEC_MEM_DWN_SFTENA — Enable power down PD_FEC's memory by software.
  [13] PD_VI_MEM_DWN_SFTENA — Enable power down PD_VI's memory by software.
  [12] PD_AV1_MEM_DWN_SFTENA — Enable power down PD_AV1's memory by software.
  [11] PD_RGA30_MEM_DWN_SFTENA — Enable power down PD_RGA30's memory by software.
  [9] PD_RKVDEC1_MEM_DWN_SFTENA — Enable power down PD_RKVDEC1's memory by software.
  [8] PD_RKVDEC0_MEM_DWN_SFTENA — Enable power down PD_RKVDEC0's memory by software.
  [7] PD_VENC1_MEM_DWN_SFTENA — Enable power down PD_VENC1's memory by software.
  [6] PD_VENC0_MEM_DWN_SFTENA — Enable power down PD_VENC0's memory by software.
  [5] PD_NPU2_MEM_DWN_SFTENA — Enable power down PD_NPU2's memory by software.
  [4] PD_NPU1_MEM_DWN_SFTENA — Enable power down PD_NPU1's memory by software.
  [3] PD_NPUTOP_MEM_DWN_SFTENA — Enable power down PD_NPUTOP's memory by software.
0x81A4 PMU_MEM_PWR_GATE_SFTCON1 — Memory software power control register 1
  [all] fields
    0=DISABLE; 1=ENABLE
  [15] PD_CENTER_MEM_DWN_SFTENA — Enable power down PD_CENTER's memory by software.
  [14] PD_CRYPTO_MEM_DWN_SFTENA — Enable power down PD_CRYPTO's memory by software.
  [13] PD_SDMMC_MEM_DWN_SFTENA — Enable power down PD_SDMMC's memory by software.
  [11] PD_USB_MEM_DWN_SFTENA — Enable power down PD_USB's memory by software.
  [10] PD_SDIO_MEM_DWN_SFTENA — Enable power down PD_SDIO's memory by software.
  [9] PD_NVM0_MEM_DWN_SFTENA — Enable power down PD_NVM0's memory by software.
  [7] PD_PCIE_MEM_DWN_SFTENA — Enable power down PD_PCIE's memory by software.
  [6] PD_GMAC_MEM_DWN_SFTENA — Enable power down PD_GMAC's memory by software.
  [5] PD_PHP_MEM_DWN_SFTENA — Enable power down PD_PHP's memory by software.
  [4] PD_AUDIO_MEM_DWN_SFTENA — Enable power down PD_AUDIO's memory by software.
  [3] PD_VO1_MEM_DWN_SFTENA — Enable power down PD_VO1's memory by software.
  [2] PD_VO0_MEM_DWN_SFTENA — Enable power down PD_VO0's memory by software.
  [1] PD_VOP_MEM_DWN_SFTENA — Enable power down PD_VOP's memory by software.
  [0] PD_RGA31_MEM_DWN_SFTENA — Enable power down PD_RGA31's memory by software.
0x81A8 PMU_MEM_PWR_GATE_SFTCON2 — Memory software power control register 2
  [1] PD_DDR23_MEM_DWN_SFTENA — Enable power down VD_DDR23's memory by software.
    0=DISABLE; 1=ENABLE
  [0] PD_DDR01_MEM_DWN_SFTENA — Enable power down VD_DDR01's memory by software.
    0=DISABLE; 1=ENABLE
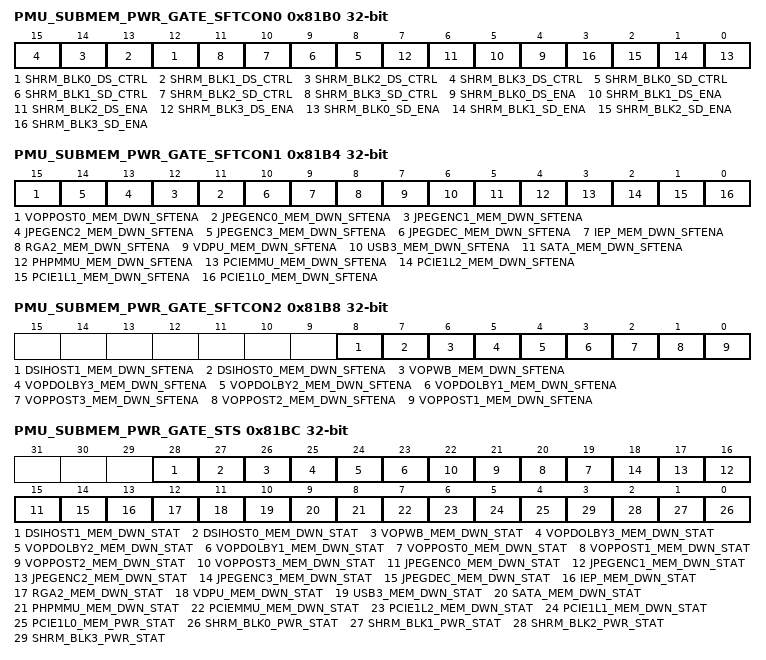
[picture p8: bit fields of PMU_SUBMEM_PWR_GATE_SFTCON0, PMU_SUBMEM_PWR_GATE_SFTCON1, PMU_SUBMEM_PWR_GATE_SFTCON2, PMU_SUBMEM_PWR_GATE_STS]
0x81B0 PMU_SUBMEM_PWR_GATE_SFTCON0 — Submodule memory software power control register 0
  [n+12] SHRM_BLK{n}_DS_CTRL (n=0..3) — Control share memory block {n} deep sleep mode by software.
    0=INVALID; 1=VALID
  [n+8] SHRM_BLK{n}_SD_CTRL (n=0..3) — Control share memory block {n} shutdown mode by software.
    0=INVALID; 1=VALID
  [n+4] SHRM_BLK{n}_DS_ENA (n=0..3) — Enable share memory block {n} deep sleep mode by software. It should be set to 1 before shrm_blk{n}_ds_ctrl set to 1, and set to 0 after shrm_blk{n}_ds_ctrl set to 0.
    0=DISABLE; 1=ENABLE
  [n] SHRM_BLK{n}_SD_ENA (n=0..3) — Enable share memory block {n} shutdown mode by software. It should be set to 1 before shrm_blk{n}_sd_ctrl set to 1, and set to 0 after shrm_blk{n}_sd_ctrl set to 0.
    0=DISABLE; 1=ENABLE
0x81B4 PMU_SUBMEM_PWR_GATE_SFTCON1 — Submodule memory software power control register 1
  [all] fields
    0=DISABLE; 1=ENABLE
  [15] VOPPOST0_MEM_DWN_SFTENA — Enable shutdown VOPPOST0 memory by software.
  [n+11] JPEGENC{n}_MEM_DWN_SFTENA (n=0..3) — Enable shutdown JPEGENC{n} memory by software.
  [10] JPEGDEC_MEM_DWN_SFTENA — Enable shutdown JPEGDEC memory by software.
  [9] IEP_MEM_DWN_SFTENA — Enable shutdown IEP memory by software.
  [8] RGA2_MEM_DWN_SFTENA — Enable shutdown RGA2 memory by software.
  [7] VDPU_MEM_DWN_SFTENA — Enable shutdown VDPU memory by software.
  [6] USB3_MEM_DWN_SFTENA — Enable shutdown USB3OTG_2 memory by software.
  [5] SATA_MEM_DWN_SFTENA — Enable shutdown SATA_0/1/2 memory by software.
  [4] PHPMMU_MEM_DWN_SFTENA — Enable shutdown PHPMMU memory by software.
  [3] PCIEMMU_MEM_DWN_SFTENA — Enable shutdown PCIEMMU memory by software.
  [2] PCIE1L2_MEM_DWN_SFTENA — Enable shutdown PCIE3_1L2 memory by software.
  [1] PCIE1L1_MEM_DWN_SFTENA — Enable shutdown PCIE3_1L1 memory by software.
  [0] PCIE1L0_MEM_DWN_SFTENA — Enable shutdown PCIE3_1L0 memory by software.
0x81B8 PMU_SUBMEM_PWR_GATE_SFTCON2 — Submodule memory software power control register 2
  [all] fields
    0=DISABLE; 1=ENABLE
  [8] DSIHOST1_MEM_DWN_SFTENA — Enable shutdown DSIHOST1 memory by software.
  [7] DSIHOST0_MEM_DWN_SFTENA — Enable shutdown DSIHOST0 memory by software.
  [6] VOPWB_MEM_DWN_SFTENA — Enable shutdown VOPWB memory by software.
  [5] VOPDOLBY3_MEM_DWN_SFTENA — Enable shutdown VOPDOLBY3 memory by software.
  [4] VOPDOLBY2_MEM_DWN_SFTENA — Enable shutdown VOPDOLBY2 memory by software.
  [3] VOPDOLBY1_MEM_DWN_SFTENA — Enable shutdown VOPDOLBY1 memory by software.
  [2] VOPPOST3_MEM_DWN_SFTENA — Enable shutdown VOPPOST3 memory by software.
  [1] VOPPOST2_MEM_DWN_SFTENA — Enable shutdown VOPPOST2 memory by software.
  [0] VOPPOST1_MEM_DWN_SFTENA — Enable shutdown VOPPOST1 memory by software.
0x81BC PMU_SUBMEM_PWR_GATE_STS — Submodule memory power status register
  [all] fields
    0=POWER_UP; 1=POWER_DOWN
  [28] DSIHOST1_MEM_DWN_STAT ro — DSIHOST1 memory power status.
  [27] DSIHOST0_MEM_DWN_STAT ro — DSIHOST0 memory power status.
  [26] VOPWB_MEM_DWN_STAT ro — VOPWB memory power status.
  [25] VOPDOLBY3_MEM_DWN_STAT ro — VOPDOLBY3 memory power status.
  [24] VOPDOLBY2_MEM_DWN_STAT ro — VOPDOLBY2 memory power status.
  [23] VOPDOLBY1_MEM_DWN_STAT ro — VOPDOLBY1 memory power status.
  [n+19] VOPPOST{n}_MEM_DWN_STAT ro (n=0..3) — VOPPOST{n} memory power status.
  [n+15] JPEGENC{n}_MEM_DWN_STAT ro (n=0..3) — JPEGENC{n} memory power status.
  [14] JPEGDEC_MEM_DWN_STAT ro — JPEGDEC memory power status.
  [13] IEP_MEM_DWN_STAT ro — IEP memory power status.
  [12] RGA2_MEM_DWN_STAT ro — RGA2 memory power status.
  [11] VDPU_MEM_DWN_STAT ro — VDPU memory power status.
  [10] USB3_MEM_DWN_STAT ro — USB3OTG_2 memory power status.
  [9] SATA_MEM_DWN_STAT ro — SATA_0/1/2 memory power status.
  [8] PHPMMU_MEM_DWN_STAT ro — PHPMMU memory power status.
  [7] PCIEMMU_MEM_DWN_STAT ro — PCIEMMU memory power status.
  [6] PCIE1L2_MEM_DWN_STAT ro — PCIE3_1L2 memory power status.
  [5] PCIE1L1_MEM_DWN_STAT ro — PCIE3_1L1 memory power status.
  [4] PCIE1L0_MEM_PWR_STAT ro — PCIE3_1L0 memory power status.
  [n] SHRM_BLK{n}_PWR_STAT ro (n=0..3) — Share memory block {n} power status.
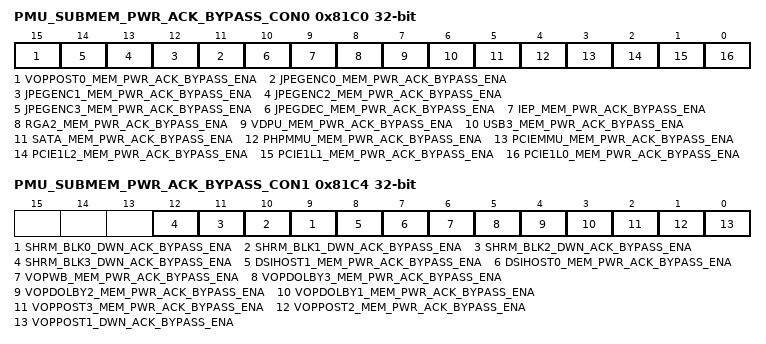
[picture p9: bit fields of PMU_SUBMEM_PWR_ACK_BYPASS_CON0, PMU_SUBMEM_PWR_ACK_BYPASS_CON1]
0x81C0 PMU_SUBMEM_PWR_ACK_BYPASS_CON0 — Submodule memory power acknowledge bypass control register 0
  [all] fields
    0=DISABLE; 1=ENABLE
  [15] VOPPOST0_MEM_PWR_ACK_BYPASS_ENA — Enable bypass VOPPOST0 memory power up or power down acknowledge. If asserted, it does not need to wait for VOPPOST0 memory power up or power down acknowledge for PD_VOP power up or power down flow.
  [n+11] JPEGENC{n}_MEM_PWR_ACK_BYPASS_ENA (n=0..3) — Enable bypass JPEGENC{n} memory power up or power down acknowledge. If asserted, it does not need to wait for JPEGENC{n} memory power up or power down acknowledge for PD_VDPU power up or power down flow.
  [10] JPEGDEC_MEM_PWR_ACK_BYPASS_ENA — Enable bypass JPEGDEC memory power up or power down acknowledge. If asserted, it does not need to wait for JPEGDEC memory power up or power down acknowledge for PD_VDPU power up or power down flow.
  [9] IEP_MEM_PWR_ACK_BYPASS_ENA — Enable bypass IEP memory power up or power down acknowledge. If asserted, it does not need to wait for IEP memory power up or power down acknowledge for PD_VDPU power up or power down flow.
  [8] RGA2_MEM_PWR_ACK_BYPASS_ENA — Enable bypass RGA2 memory power up or power down acknowledge. If asserted, it does not need to wait for RGA2 memory power up or power down acknowledge for PD_VDPU power up or power down flow.
  [7] VDPU_MEM_PWR_ACK_BYPASS_ENA — Enable bypass VDPU memory power up or power down acknowledge. If asserted, it does not need to wait for VDPU memory power up or power down acknowledge for PD_VDPU power up or power down flow.
  [6] USB3_MEM_PWR_ACK_BYPASS_ENA — Enable bypass USB3OTG_2 memory power up or power down acknowledge. If asserted, it does not need to wait for USB3OTG_2 memory power up or power down acknowledge for PD_PHP power up or power down flow.
  [5] SATA_MEM_PWR_ACK_BYPASS_ENA — Enable bypass SATA_0/1/2 memory power up or power down acknowledge. If asserted, it does not need to wait for SATA_0/1/2 memory power up or power down acknowledge for PD_PHP power up or power down flow.
  [4] PHPMMU_MEM_PWR_ACK_BYPASS_ENA — Enable bypass PHPMMU memory power up or power down acknowledge. If asserted, it does not need to wait for PHPMMU memory power up or power down acknowledge for PD_PHP power up or power down flow.
  [3] PCIEMMU_MEM_PWR_ACK_BYPASS_ENA — Enable bypass PCIEMMU memory power up or power down acknowledge. If asserted, it does not need to wait for PCIEMMU memory power up or power down acknowledge for PD_PHP power up or power down flow.
  [2] PCIE1L2_MEM_PWR_ACK_BYPASS_ENA — Enable bypass PCIE3_1L2 memory power up or power down acknowledge. If asserted, it does not need to wait for PCIE3_1L2 memory power up or power down acknowledge for PD_PHP power up or power down flow.
  [1] PCIE1L1_MEM_PWR_ACK_BYPASS_ENA — Enable bypass PCIE3_1L1 memory power up or power down acknowledge. If asserted, it does not need to wait for PCIE3_1L1 memory power up or power down acknowledge for PD_PHP power up or power down flow.
  [0] PCIE1L0_MEM_PWR_ACK_BYPASS_ENA — Enable bypass PCIE3_1L0 memory power up or power down acknowledge. If asserted, it does not need to wait for PCIE3_1L0 memory power up or power down acknowledge for PD_PHP power up or power down flow.
0x81C4 PMU_SUBMEM_PWR_ACK_BYPASS_CON1 — Submodule memory power acknowledge bypass control register 1
  [all] fields
    0=DISABLE; 1=ENABLE
  [n+9] SHRM_BLK{n}_DWN_ACK_BYPASS_ENA (n=0..3) — Enable bypass share memory block{n} memory power up or power down acknowledge. If asserted, it does not need to wait for share memory block{n} memory power up or power down acknowledge for PD_CENTER power up or power down flow.
  [8] DSIHOST1_MEM_PWR_ACK_BYPASS_ENA — Enable bypass DSIHOST1 memory power up or power down acknowledge. If asserted, it does not need to wait for DSIHOST1 memory power up or power down acknowledge for PD_VOP power up or power down flow.
  [7] DSIHOST0_MEM_PWR_ACK_BYPASS_ENA — Enable bypass DSIHOST0 memory power up or power down acknowledge. If asserted, it does not need to wait for DSIHOST0 memory power up or power down acknowledge for PD_VOP power up or power down flow.
  [6] VOPWB_MEM_PWR_ACK_BYPASS_ENA — Enable bypass VOPWB memory power up or power down acknowledge. If asserted, it does not need to wait for VOPWB memory power up or power down acknowledge for PD_VOP power up or power down flow.
  [5] VOPDOLBY3_MEM_PWR_ACK_BYPASS_ENA — Enable bypass VOPDOLBY3 memory power up or power down acknowledge. If asserted, it does not need to wait for VOPDOLBY3 memory power up or power down acknowledge for PD_VOP power up or power down flow.
  [4] VOPDOLBY2_MEM_PWR_ACK_BYPASS_ENA — Enable bypass VOPDOLBY2 memory power up or power down acknowledge. If asserted, it does not need to wait for VOPDOLBY2 memory power up or power down acknowledge for PD_VOP power up or power down flow.
  [3] VOPDOLBY1_MEM_PWR_ACK_BYPASS_ENA — Enable bypass VOPDOLBY1 memory power up or power down acknowledge. If asserted, it does not need to wait for VOPDOLBY1 memory power up or power down acknowledge for PD_VOP power up or power down flow.
  [2] VOPPOST3_MEM_PWR_ACK_BYPASS_ENA — Enable bypass VOPPOST3 memory power up or power down acknowledge. If asserted, it does not need to wait for VOPPOST3 memory power up or power down acknowledge for PD_VOP power up or power down flow.
  [1] VOPPOST2_MEM_PWR_ACK_BYPASS_ENA — Enable bypass VOPPOST2 memory power up or power down acknowledge. If asserted, it does not need to wait for VOPPOST2 memory power up or power down acknowledge for PD_VOP power up or power down flow.
  [0] VOPPOST1_DWN_ACK_BYPASS_ENA — Enable bypass VOPPOST1 memory power up or power down acknowledge. If asserted, it does not need to wait for VOPPOST1 memory power up or power down acknowledge for PD_VOP power up or power down flow.
